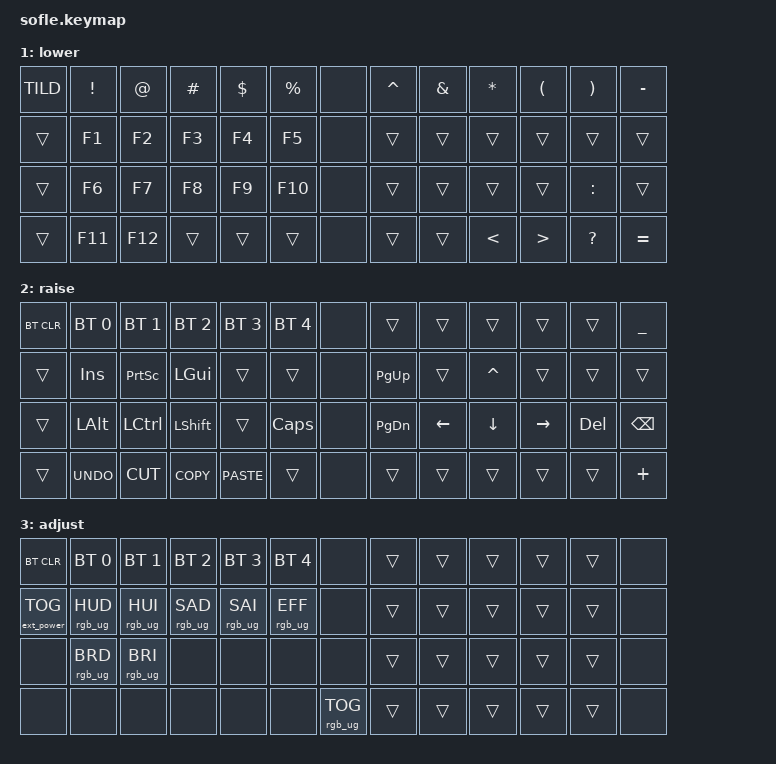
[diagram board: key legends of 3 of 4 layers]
/*
 * Copyright (c) 2020 The ZMK Contributors
 *
 * SPDX-License-Identifier: MIT
 */

#include <behaviors.dtsi>
#include <dt-bindings/zmk/keys.h>
#include <dt-bindings/zmk/bt.h>
#include <dt-bindings/zmk/rgb.h>
#include <dt-bindings/zmk/ext_power.h>

#define BASE 0
#define LOWER 1
#define RAISE 2
#define ADJUST 3

/ {
    // Activate ADJUST layer by pressing LOWER + RAISE
    conditional_layers {
        compatible = "zmk,conditional-layers";
        adjust_layer {
            if-layers = <LOWER RAISE>;
            then-layer = <ADJUST>;
        };
    };

    keymap {
        compatible = "zmk,keymap";

        default_layer {
            display-name = "default";
            bindings = <
                &kp GRAVE &kp N1    &kp N2    &kp N3    &kp N4    &kp N5    &none      &kp N6    &kp N7    &kp N8    &kp N9    &kp N0    &none
                &kp ESC   &kp Q     &kp W     &kp E     &kp R     &kp T     &none      &kp Y     &kp U     &kp I     &kp O     &kp P     &kp BSPC
                &kp TAB   &kp A     &kp S     &kp D     &kp F     &kp G     &none      &kp H     &kp J     &kp K     &kp L     &kp SEMI  &kp SQT
                &kp LSHFT &kp Z     &kp X     &kp C     &kp V     &kp B     &kp C_MUTE &none      &kp N     &kp M     &kp COMMA &kp DOT   &kp FSLH &kp RSHFT
                          &kp LGUI  &kp LALT  &kp LCTRL &mo LOWER &kp SPACE &kp RET  &mo RAISE &kp RCTRL &kp RALT  &kp RGUI
            >;
            sensor-bindings = <&inc_dec_kp C_VOL_UP C_VOL_DN &inc_dec_kp PG_UP PG_DN>;
        };

        lower_layer {
            display-name = "lower";
            bindings = <
                /* Row1 */
                &kp TILD  &kp EXCL &kp AT    &kp HASH &kp DLLR &kp PRCNT &none      &kp CARET &kp AMPS  &kp ASTRK &kp LPAR  &kp RPAR  &kp MINUS
                /* Row2 */
                &trans    &kp F1   &kp F2    &kp F3   &kp F4   &kp F5   &none      &trans    &trans    &trans    &trans    &trans    &trans
                /* Row3 */
                &trans    &kp F6   &kp F7    &kp F8   &kp F9   &kp F10  &none      &trans    &trans    &trans    &trans    &kp COLON &trans
                /* Row4 */
                &trans    &kp F11  &kp F12   &trans   &trans   &trans   &none      &trans    &trans    &kp LT    &kp GT    &kp QMARK &kp EQUAL
            >;
            sensor-bindings = <&inc_dec_kp C_VOL_UP C_VOL_DN &inc_dec_kp PG_UP PG_DN>;
        };

        raise_layer {
            display-name = "raise";
            bindings = <
                /* Row1 */
                &bt BT_CLR       &bt BT_SEL 0 &bt BT_SEL 1 &bt BT_SEL 2 &bt BT_SEL 3 &bt BT_SEL 4 &none      &trans    &trans    &trans    &trans    &trans    &kp UNDERSCORE
                /* Row2 */
                &trans           &kp INS     &kp PSCRN    &kp LGUI     &trans      &trans      &none      &kp PG_UP  &trans    &kp CARET  &trans    &trans    &trans
                /* Row3 */
                &trans           &kp LALT    &kp LCTRL    &kp LSHFT    &trans      &kp CAPS    &none      &kp PG_DN  &kp LEFT   &kp DOWN   &kp RIGHT  &kp DEL   &kp BSPC
                /* Row4 */
                &trans           &kp K_UNDO  &kp K_CUT    &kp K_COPY   &kp K_PASTE &trans      &none      &trans    &trans    &trans    &trans    &trans    &kp PLUS
            >;
        };

        adjust_layer {
            display-name = "adjust";
            bindings = <
                /* Row1 */
                &bt BT_CLR       &bt BT_SEL 0 &bt BT_SEL 1 &bt BT_SEL 2 &bt BT_SEL 3 &bt BT_SEL 4 &none      &trans    &trans    &trans    &trans    &trans    &none
                /* Row2 */
                &ext_power EP_TOG &rgb_ug RGB_HUD &rgb_ug RGB_HUI &rgb_ug RGB_SAD &rgb_ug RGB_SAI &rgb_ug RGB_EFF &none      &trans    &trans    &trans    &trans    &trans    &none
                /* Row3 */
                &none            &rgb_ug RGB_BRD &rgb_ug RGB_BRI &none           &none           &none           &none      &trans    &trans    &trans    &trans    &trans    &none
                /* Row4 */
                &none            &none           &none           &none           &none           &none           &rgb_ug RGB_TOG &trans    &trans    &trans    &trans    &trans    &none
            >;
        };
    };
};
